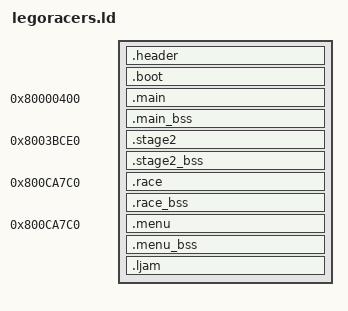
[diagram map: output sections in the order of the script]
SECTIONS
{
    __romPos = 0;
    header_ROM_START = __romPos;
    header_VRAM = ADDR(.header);
    .header : AT(header_ROM_START) SUBALIGN(16)
    {
        header_DATA_START = .;
        header_s = .;
        build/asm/header.s.o(.data);
        header_DATA_END = .;
    }
    __romPos += SIZEOF(.header);
    header_ROM_END = __romPos;
    header_VRAM_END = .;

    boot_ROM_START = __romPos;
    boot_VRAM = ADDR(.boot);
    .boot : AT(boot_ROM_START) SUBALIGN(16)
    {
        boot_DATA_START = .;
        boot_bin = .;
        build/assets/boot.bin.o(.data);
        boot_DATA_END = .;
    }
    __romPos += SIZEOF(.boot);
    boot_ROM_END = __romPos;
    boot_VRAM_END = .;

    main_ROM_START = __romPos;
    main_VRAM = ADDR(.main);
    .main 0x80000400 : AT(main_ROM_START) SUBALIGN(16)
    {
        main_TEXT_START = .;
        build/asm/1000.s.o(.text);
        main_DATA_START = .;
        main_RODATA_START = .;
        build/asm/data/libc.rdata.s.o(.rdata);
        build/asm/data/main_030.rdata.s.o(.rdata);
        build/asm/data/main/1150.rdata.s.o(.rdata);
        build/asm/data/main/1360.rdata.s.o(.rdata);
        build/asm/data/main/1800.rdata.s.o(.rdata);
        build/asm/data/main/1890.rdata.s.o(.rdata);
        build/asm/data/main/1A40.rdata.s.o(.rdata);
        build/asm/data/main/1C20.rdata.s.o(.rdata);
        build/asm/data/main/1C60.rdata.s.o(.rdata);
        build/asm/data/main/1CD0.rdata.s.o(.rdata);
        build/asm/data/main/1CF0.rdata.s.o(.rdata);
        build/asm/data/main/1D40.rdata.s.o(.rdata);
        build/asm/data/libsn/divdi3.rdata.s.o(.rdata);
        build/asm/data/libsn/udivdi3.rdata.s.o(.rdata);
        build/asm/data/libsn/umoddi3.rdata.s.o(.rdata);
        build/asm/data/libultra/setintmask.rodata.s.o(.rodata);
        build/asm/data/libultra/rodata.rodata.s.o(.rodata);
        build/asm/data/libultra/rodata2.rodata.s.o(.rodata);
        main_RODATA_END = .;
        build/asm/libc.s.o(.text);
        build/asm/main/010.s.o(.text);
        build/asm/main/020.s.o(.text);
        build/asm/main/030.s.o(.text);
        build/asm/main/040.s.o(.text);
        build/asm/main/050.s.o(.text);
        build/asm/main/060.s.o(.text);
        build/asm/main/070.s.o(.text);
        build/asm/main/080.s.o(.text);
        build/asm/main/090.s.o(.text);
        build/asm/main/100.s.o(.text);
        build/asm/main/110.s.o(.text);
        build/asm/main/120.s.o(.text);
        build/asm/main/130.s.o(.text);
        build/asm/main/140.s.o(.text);
        rspboot_bin = .;
        build/assets/rspboot.bin.o(.data);
        gspF3DEX2_NoN_fifoTextStart_bin = .;
        build/assets/gspF3DEX2_NoN_fifoTextStart.bin.o(.data);
        n_aspMain_text_text__bin = .;
        build/assets/n_aspMain.text.bin.o(.data);
        build/asm/libmus/player.s.o(.text);
        build/asm/libmus/player_fx.s.o(.text);
        build/asm/libmus/aud_dma.s.o(.text);
        build/asm/libmus/aud_sched.s.o(.text);
        build/asm/libmus/aud_thread.s.o(.text);
        build/asm/libmus/aud_samples.s.o(.text);
        build/asm/libmus/lib_memory.s.o(.text);
        build/asm/libaudio/n_auxbux.s.o(.text);
        build/asm/libaudio/n_drverNew.s.o(.text);
        build/asm/libaudio/n_env.s.o(.text);
        build/asm/libaudio/0x147A0.s.o(.text);
        build/asm/libaudio/n_resample.s.o(.text);
        build/asm/libaudio/x147A0.s.o(.text);
        build/asm/libaudio/n_synaddplayer.s.o(.text);
        build/asm/libaudio/n_synallocvoice.s.o(.text);
        build/asm/libaudio/0x15DA0.s.o(.text);
        build/asm/libaudio/0x15F50.s.o(.text);
        build/asm/libaudio/0x15FE0.s.o(.text);
        build/asm/libaudio/n_synthesiser.s.o(.text);
        build/asm/libaudio/n_save.s.o(.text);
        build/asm/libaudio/n_mainbus.s.o(.text);
        build/asm/libaudio/n_syncallocfx.s.o(.text);
        build/asm/libultra/osSetIntMask.s.o(.text);
        build/asm/libultra/osPiRawStartDma.s.o(.text);
        build/asm/libultra/16C20.s.o(.text);
        build/asm/libultra/16CC0.s.o(.text);
        build/asm/libultra/16E60.s.o(.text);
        build/asm/libultra/17220.s.o(.text);
        build/asm/libultra/172B0.s.o(.text);
        build/asm/libultra/17420.s.o(.text);
        build/asm/libultra/17590.s.o(.text);
        build/asm/libultra/17680.s.o(.text);
        build/asm/libultra/17730.s.o(.text);
        build/asm/libultra/17870.s.o(.text);
        build/asm/libultra/17910.s.o(.text);
        build/asm/libultra/17930.s.o(.text);
        build/asm/libultra/18160.s.o(.text);
        build/asm/libultra/18C70.s.o(.text);
        build/asm/libultra/18D80.s.o(.text);
        build/asm/libultra/19A50.s.o(.text);
        build/asm/libultra/19E70.s.o(.text);
        build/asm/libultra/1AA10.s.o(.text);
        build/asm/libultra/1AB90.s.o(.text);
        build/asm/libultra/1ABD0.s.o(.text);
        build/asm/libultra/1AC20.s.o(.text);
        build/asm/libultra/1AC60.s.o(.text);
        build/asm/libultra/1B2A0.s.o(.text);
        build/asm/libultra/1B2B0.s.o(.text);
        build/asm/libultra/1B350.s.o(.text);
        build/asm/libultra/1B480.s.o(.text);
        build/asm/libultra/1B500.s.o(.text);
        build/asm/libultra/1B530.s.o(.text);
        build/asm/libultra/1B7B0.s.o(.text);
        build/asm/libultra/1BAC0.s.o(.text);
        build/asm/libultra/1BB20.s.o(.text);
        build/asm/libultra/1BB30.s.o(.text);
        build/asm/libultra/1BF00.s.o(.text);
        build/asm/libultra/1C450.s.o(.text);
        build/asm/libultra/1C4E0.s.o(.text);
        build/asm/libultra/1CF10.s.o(.text);
        build/asm/libultra/1D160.s.o(.text);
        build/asm/libultra/1D320.s.o(.text);
        build/asm/libultra/1DDA0.s.o(.text);
        build/asm/libultra/1DDD0.s.o(.text);
        build/asm/libultra/1DF10.s.o(.text);
        build/asm/libultra/1E880.s.o(.text);
        build/asm/libultra/1E9B0.s.o(.text);
        build/asm/libultra/1EB90.s.o(.text);
        build/asm/libultra/1EDD0.s.o(.text);
        build/asm/libultra/1F110.s.o(.text);
        build/asm/libultra/1F1E0.s.o(.text);
        build/asm/libultra/1F200.s.o(.text);
        build/asm/libultra/1F250.s.o(.text);
        build/asm/libultra/1FD10.s.o(.text);
        build/asm/libultra/1FD30.s.o(.text);
        build/asm/libultra/1FDE0.s.o(.text);
        build/asm/libultra/1FED0.s.o(.text);
        build/asm/libultra/20080.s.o(.text);
        build/asm/libultra/200A0.s.o(.text);
        build/asm/libultra/20170.s.o(.text);
        build/asm/libultra/20290.s.o(.text);
        build/asm/libultra/20350.s.o(.text);
        build/asm/libultra/20390.s.o(.text);
        build/asm/libultra/203E0.s.o(.text);
        build/asm/libultra/20470.s.o(.text);
        build/asm/libultra/20480.s.o(.text);
        build/asm/libultra/20520.s.o(.text);
        build/asm/libultra/20820.s.o(.text);
        build/asm/libultra/20830.s.o(.text);
        build/asm/libultra/208F0.s.o(.text);
        build/asm/libultra/20940.s.o(.text);
        build/asm/libultra/20980.s.o(.text);
        build/asm/libultra/20A90.s.o(.text);
        build/asm/libultra/20AD0.s.o(.text);
        build/asm/libultra/20E10.s.o(.text);
        build/asm/libultra/20E20.s.o(.text);
        build/asm/libultra/20E80.s.o(.text);
        build/asm/libultra/20ED0.s.o(.text);
        build/asm/libultra/21040.s.o(.text);
        build/asm/libultra/21090.s.o(.text);
        build/asm/libultra/213A0.s.o(.text);
        build/asm/libultra/21400.s.o(.text);
        build/asm/libultra/21790.s.o(.text);
        build/asm/libultra/21880.s.o(.text);
        build/asm/libultra/21CB0.s.o(.text);
        build/asm/libultra/21ED0.s.o(.text);
        build/asm/libultra/224B0.s.o(.text);
        build/asm/libultra/22670.s.o(.text);
        build/asm/libultra/22950.s.o(.text);
        build/asm/libultra/22A60.s.o(.text);
        build/asm/libultra/22E30.s.o(.text);
        build/asm/libultra/236C0.s.o(.text);
        build/asm/libultra/238D0.s.o(.text);
        build/asm/libultra/23940.s.o(.text);
        build/asm/libultra/243D0.s.o(.text);
        build/asm/libultra/245C0.s.o(.text);
        build/asm/libultra/24830.s.o(.text);
        build/asm/libultra/24B20.s.o(.text);
        build/asm/libultra/24B30.s.o(.text);
        build/asm/libultra/24BA0.s.o(.text);
        build/asm/libultra/24BC0.s.o(.text);
        build/asm/libultra/24C10.s.o(.text);
        build/asm/libsn/divdi3.s.o(.text);
        build/asm/libsn/udivdi3.s.o(.text);
        build/asm/libsn/umoddi3.s.o(.text);
        build/asm/alloc.s.o(.text);
        build/asm/__builtin_delete.s.o(.text);
        main_TEXT_END = .;
        main_25D30_data__s = .;
        build/asm/data/main/25D30.data.s.o(.data);
        main_25E40_data__s = .;
        build/asm/data/main/25E40.data.s.o(.data);
        main_27EA0_data__s = .;
        build/asm/data/main/27EA0.data.s.o(.data);
        main_306C0_data__s = .;
        build/asm/data/main/306C0.data.s.o(.data);
        main_30950_data__s = .;
        build/asm/data/main/30950.data.s.o(.data);
        main_30960_data__s = .;
        build/asm/data/main/30960.data.s.o(.data);
        main_30970_data__s = .;
        build/asm/data/main/30970.data.s.o(.data);
        main_309D0_data__s = .;
        build/asm/data/main/309D0.data.s.o(.data);
        main_309E0_data__s = .;
        build/asm/data/main/309E0.data.s.o(.data);
        main_309F0_data__s = .;
        build/asm/data/main/309F0.data.s.o(.data);
        main_30C00_data__s = .;
        build/asm/data/main/30C00.data.s.o(.data);
        gspF3DEX2_NoN_fifoDataStart_bin = .;
        build/assets/gspF3DEX2_NoN_fifoDataStart.bin.o(.data);
        n_aspMain_data_bin = .;
        build/assets/n_aspMain_data.bin.o(.data);
        lib_313A0_data__s = .;
        build/asm/data/lib/313A0.data.s.o(.data);
        lib_315D0_data__s = .;
        build/asm/data/lib/315D0.data.s.o(.data);
        lib_315E0_data__s = .;
        build/asm/data/lib/315E0.data.s.o(.data);
        lib_31880_data__s = .;
        build/asm/data/lib/31880.data.s.o(.data);
        lib_31890_data__s = .;
        build/asm/data/lib/31890.data.s.o(.data);
        main_DATA_END = .;
    }
    main_bss_VRAM = ADDR(.main_bss);
    .main_bss (NOLOAD) : SUBALIGN(16)
    {
        main_BSS_START = .;
        build/asm/1000.s.o(.bss);
        build/asm/libc.s.o(.bss);
        build/asm/main/010.s.o(.bss);
        build/asm/main/020.s.o(.bss);
        build/asm/main/030.s.o(.bss);
        build/asm/main/040.s.o(.bss);
        build/asm/main/050.s.o(.bss);
        build/asm/main/060.s.o(.bss);
        build/asm/main/070.s.o(.bss);
        build/asm/main/080.s.o(.bss);
        build/asm/main/090.s.o(.bss);
        build/asm/main/100.s.o(.bss);
        build/asm/main/110.s.o(.bss);
        build/asm/main/120.s.o(.bss);
        build/asm/main/130.s.o(.bss);
        build/asm/main/140.s.o(.bss);
        build/asm/libmus/player.s.o(.bss);
        build/asm/libmus/player_fx.s.o(.bss);
        build/asm/libmus/aud_dma.s.o(.bss);
        build/asm/libmus/aud_sched.s.o(.bss);
        build/asm/libmus/aud_thread.s.o(.bss);
        build/asm/libmus/aud_samples.s.o(.bss);
        build/asm/libmus/lib_memory.s.o(.bss);
        build/asm/libaudio/n_auxbux.s.o(.bss);
        build/asm/libaudio/n_drverNew.s.o(.bss);
        build/asm/libaudio/n_env.s.o(.bss);
        build/asm/libaudio/0x147A0.s.o(.bss);
        build/asm/libaudio/n_resample.s.o(.bss);
        build/asm/libaudio/x147A0.s.o(.bss);
        build/asm/libaudio/n_synaddplayer.s.o(.bss);
        build/asm/libaudio/n_synallocvoice.s.o(.bss);
        build/asm/libaudio/0x15DA0.s.o(.bss);
        build/asm/libaudio/0x15F50.s.o(.bss);
        build/asm/libaudio/0x15FE0.s.o(.bss);
        build/asm/libaudio/n_synthesiser.s.o(.bss);
        build/asm/libaudio/n_save.s.o(.bss);
        build/asm/libaudio/n_mainbus.s.o(.bss);
        build/asm/libaudio/n_syncallocfx.s.o(.bss);
        build/asm/libultra/osSetIntMask.s.o(.bss);
        build/asm/libultra/osPiRawStartDma.s.o(.bss);
        build/asm/libultra/16C20.s.o(.bss);
        build/asm/libultra/16CC0.s.o(.bss);
        build/asm/libultra/16E60.s.o(.bss);
        build/asm/libultra/17220.s.o(.bss);
        build/asm/libultra/172B0.s.o(.bss);
        build/asm/libultra/17420.s.o(.bss);
        build/asm/libultra/17590.s.o(.bss);
        build/asm/libultra/17680.s.o(.bss);
        build/asm/libultra/17730.s.o(.bss);
        build/asm/libultra/17870.s.o(.bss);
        build/asm/libultra/17910.s.o(.bss);
        build/asm/libultra/17930.s.o(.bss);
        build/asm/libultra/18160.s.o(.bss);
        build/asm/libultra/18C70.s.o(.bss);
        build/asm/libultra/18D80.s.o(.bss);
        build/asm/libultra/19A50.s.o(.bss);
        build/asm/libultra/19E70.s.o(.bss);
        build/asm/libultra/1AA10.s.o(.bss);
        build/asm/libultra/1AB90.s.o(.bss);
        build/asm/libultra/1ABD0.s.o(.bss);
        build/asm/libultra/1AC20.s.o(.bss);
        build/asm/libultra/1AC60.s.o(.bss);
        build/asm/libultra/1B2A0.s.o(.bss);
        build/asm/libultra/1B2B0.s.o(.bss);
        build/asm/libultra/1B350.s.o(.bss);
        build/asm/libultra/1B480.s.o(.bss);
        build/asm/libultra/1B500.s.o(.bss);
        build/asm/libultra/1B530.s.o(.bss);
        build/asm/libultra/1B7B0.s.o(.bss);
        build/asm/libultra/1BAC0.s.o(.bss);
        build/asm/libultra/1BB20.s.o(.bss);
        build/asm/libultra/1BB30.s.o(.bss);
        build/asm/libultra/1BF00.s.o(.bss);
        build/asm/libultra/1C450.s.o(.bss);
        build/asm/libultra/1C4E0.s.o(.bss);
        build/asm/libultra/1CF10.s.o(.bss);
        build/asm/libultra/1D160.s.o(.bss);
        build/asm/libultra/1D320.s.o(.bss);
        build/asm/libultra/1DDA0.s.o(.bss);
        build/asm/libultra/1DDD0.s.o(.bss);
        build/asm/libultra/1DF10.s.o(.bss);
        build/asm/libultra/1E880.s.o(.bss);
        build/asm/libultra/1E9B0.s.o(.bss);
        build/asm/libultra/1EB90.s.o(.bss);
        build/asm/libultra/1EDD0.s.o(.bss);
        build/asm/libultra/1F110.s.o(.bss);
        build/asm/libultra/1F1E0.s.o(.bss);
        build/asm/libultra/1F200.s.o(.bss);
        build/asm/libultra/1F250.s.o(.bss);
        build/asm/libultra/1FD10.s.o(.bss);
        build/asm/libultra/1FD30.s.o(.bss);
        build/asm/libultra/1FDE0.s.o(.bss);
        build/asm/libultra/1FED0.s.o(.bss);
        build/asm/libultra/20080.s.o(.bss);
        build/asm/libultra/200A0.s.o(.bss);
        build/asm/libultra/20170.s.o(.bss);
        build/asm/libultra/20290.s.o(.bss);
        build/asm/libultra/20350.s.o(.bss);
        build/asm/libultra/20390.s.o(.bss);
        build/asm/libultra/203E0.s.o(.bss);
        build/asm/libultra/20470.s.o(.bss);
        build/asm/libultra/20480.s.o(.bss);
        build/asm/libultra/20520.s.o(.bss);
        build/asm/libultra/20820.s.o(.bss);
        build/asm/libultra/20830.s.o(.bss);
        build/asm/libultra/208F0.s.o(.bss);
        build/asm/libultra/20940.s.o(.bss);
        build/asm/libultra/20980.s.o(.bss);
        build/asm/libultra/20A90.s.o(.bss);
        build/asm/libultra/20AD0.s.o(.bss);
        build/asm/libultra/20E10.s.o(.bss);
        build/asm/libultra/20E20.s.o(.bss);
        build/asm/libultra/20E80.s.o(.bss);
        build/asm/libultra/20ED0.s.o(.bss);
        build/asm/libultra/21040.s.o(.bss);
        build/asm/libultra/21090.s.o(.bss);
        build/asm/libultra/213A0.s.o(.bss);
        build/asm/libultra/21400.s.o(.bss);
        build/asm/libultra/21790.s.o(.bss);
        build/asm/libultra/21880.s.o(.bss);
        build/asm/libultra/21CB0.s.o(.bss);
        build/asm/libultra/21ED0.s.o(.bss);
        build/asm/libultra/224B0.s.o(.bss);
        build/asm/libultra/22670.s.o(.bss);
        build/asm/libultra/22950.s.o(.bss);
        build/asm/libultra/22A60.s.o(.bss);
        build/asm/libultra/22E30.s.o(.bss);
        build/asm/libultra/236C0.s.o(.bss);
        build/asm/libultra/238D0.s.o(.bss);
        build/asm/libultra/23940.s.o(.bss);
        build/asm/libultra/243D0.s.o(.bss);
        build/asm/libultra/245C0.s.o(.bss);
        build/asm/libultra/24830.s.o(.bss);
        build/asm/libultra/24B20.s.o(.bss);
        build/asm/libultra/24B30.s.o(.bss);
        build/asm/libultra/24BA0.s.o(.bss);
        build/asm/libultra/24BC0.s.o(.bss);
        build/asm/libultra/24C10.s.o(.bss);
        build/asm/libsn/divdi3.s.o(.bss);
        build/asm/libsn/udivdi3.s.o(.bss);
        build/asm/libsn/umoddi3.s.o(.bss);
        build/asm/alloc.s.o(.bss);
        build/asm/__builtin_delete.s.o(.bss);
        main_BSS_END = .;
    }
    __romPos += SIZEOF(.main);
    __romPos = (__romPos + 15) & ~15; /* align 16 */
    main_ROM_END = __romPos;
    main_VRAM_END = .;

    stage2_ROM_START = __romPos;
    stage2_VRAM = ADDR(.stage2);
    .stage2 0x8003BCE0 : AT(stage2_ROM_START) SUBALIGN(16)
    {
        stage2_RODATA_START = .;
        build/asm/data/stage2/010a.rdata.s.o(.rdata);
        stage2_DATA_START = .;
        build/asm/data/stage2/010b.rdata.s.o(.rdata);
        build/asm/data/stage2/010c.rdata.s.o(.rdata);
        build/asm/data/stage2/030.rdata.s.o(.rdata);
        build/asm/data/stage2/040.rdata.s.o(.rdata);
        build/asm/data/stage2/050a.rdata.s.o(.rdata);
        build/asm/data/stage2/050b.rdata.s.o(.rdata);
        build/asm/data/stage2/060.rdata.s.o(.rdata);
        build/asm/data/stage2/070.rdata.s.o(.rdata);
        build/asm/data/stage2/080.rdata.s.o(.rdata);
        build/asm/data/stage2/090.rdata.s.o(.rdata);
        build/asm/data/stage2/100.rdata.s.o(.rdata);
        build/asm/data/stage2/110.rdata.s.o(.rdata);
        build/asm/data/stage2/120.rdata.s.o(.rdata);
        build/asm/data/stage2/130.rdata.s.o(.rdata);
        build/asm/data/stage2/140.rdata.s.o(.rdata);
        build/asm/data/stage2/150.rdata.s.o(.rdata);
        build/asm/data/stage2/160.rdata.s.o(.rdata);
        build/asm/data/stage2/170.rdata.s.o(.rdata);
        build/asm/data/stage2/180.rdata.s.o(.rdata);
        build/asm/data/stage2/190.rdata.s.o(.rdata);
        build/asm/data/stage2/200a.rdata.s.o(.rdata);
        build/asm/data/stage2/200b.rdata.s.o(.rdata);
        build/asm/data/stage2/210.rdata.s.o(.rdata);
        build/asm/data/stage2/220.rdata.s.o(.rdata);
        build/asm/data/stage2/230.rdata.s.o(.rdata);
        build/asm/data/stage2/240.rdata.s.o(.rdata);
        build/asm/data/stage2/250.rdata.s.o(.rdata);
        build/asm/data/stage2/260.rdata.s.o(.rdata);
        build/asm/data/stage2/270.rdata.s.o(.rdata);
        build/asm/data/stage2/280.rdata.s.o(.rdata);
        build/asm/data/stage2/290.rdata.s.o(.rdata);
        build/asm/data/stage2/300a.rdata.s.o(.rdata);
        build/asm/data/stage2/300b.rdata.s.o(.rdata);
        build/asm/data/stage2/310.rdata.s.o(.rdata);
        build/asm/data/stage2/320.rdata.s.o(.rdata);
        build/asm/data/stage2/330.rdata.s.o(.rdata);
        build/asm/data/stage2/340.rdata.s.o(.rdata);
        build/asm/data/stage2/350.rdata.s.o(.rdata);
        build/asm/data/stage2/360.rdata.s.o(.rdata);
        build/asm/data/stage2/370.rdata.s.o(.rdata);
        build/asm/data/stage2/380.rdata.s.o(.rdata);
        build/asm/data/stage2/390.rdata.s.o(.rdata);
        build/asm/data/stage2/400.rdata.s.o(.rdata);
        build/asm/data/stage2/410.rdata.s.o(.rdata);
        build/asm/data/stage2/420.rdata.s.o(.rdata);
        build/asm/data/stage2/430.rdata.s.o(.rdata);
        build/asm/data/stage2/440.rdata.s.o(.rdata);
        build/asm/data/stage2/450.rdata.s.o(.rdata);
        build/asm/data/stage2/460.rdata.s.o(.rdata);
        build/asm/data/stage2/470.rdata.s.o(.rdata);
        build/asm/data/stage2/480.rdata.s.o(.rdata);
        build/asm/data/stage2/490.rdata.s.o(.rdata);
        build/asm/data/stage2/500.rdata.s.o(.rdata);
        build/asm/data/stage2/510.rdata.s.o(.rdata);
        build/asm/data/stage2/520.rdata.s.o(.rdata);
        build/asm/data/stage2/530.rdata.s.o(.rdata);
        build/asm/data/stage2/550.rdata.s.o(.rdata);
        build/asm/data/stage2/560.rdata.s.o(.rdata);
        build/asm/data/stage2/570.rdata.s.o(.rdata);
        build/asm/data/stage2/580.rdata.s.o(.rdata);
        build/asm/data/stage2/590.rdata.s.o(.rdata);
        build/asm/data/stage2/600.rdata.s.o(.rdata);
        build/asm/data/stage2/610.rdata.s.o(.rdata);
        build/asm/data/stage2/620a.rdata.s.o(.rdata);
        build/asm/data/stage2/620b.rdata.s.o(.rdata);
        build/asm/data/stage2/630.rdata.s.o(.rdata);
        build/asm/data/stage2/640.rdata.s.o(.rdata);
        build/asm/data/stage2/650.rdata.s.o(.rdata);
        build/asm/data/stage2/660.rdata.s.o(.rdata);
        build/asm/data/stage2/670a.rdata.s.o(.rdata);
        build/asm/data/stage2/670b.rdata.s.o(.rdata);
        build/asm/data/stage2/680.rdata.s.o(.rdata);
        build/asm/data/stage2/690.rdata.s.o(.rdata);
        build/asm/data/stage2/700.rdata.s.o(.rdata);
        build/asm/data/stage2/720.rdata.s.o(.rdata);
        build/asm/data/stage2/740.rdata.s.o(.rdata);
        build/asm/data/stage2/750.rdata.s.o(.rdata);
        build/asm/data/stage2/760a.rdata.s.o(.rdata);
        build/asm/data/stage2/760b.rdata.s.o(.rdata);
        build/asm/data/stage2/760c.rdata.s.o(.rdata);
        build/asm/data/stage2/770.rdata.s.o(.rdata);
        build/asm/data/stage2/780.rdata.s.o(.rdata);
        build/asm/data/stage2/790.rdata.s.o(.rdata);
        build/asm/data/stage2/800.rdata.s.o(.rdata);
        build/asm/data/stage2/810.rdata.s.o(.rdata);
        stage2_080_ctor_ctor__data__s = .;
        build/asm/data/stage2/080.ctor.data.s.o(.data);
        stage2_180a_ctor_ctor__data__s = .;
        build/asm/data/stage2/180a.ctor.data.s.o(.data);
        stage2_180b_ctor_ctor__data__s = .;
        build/asm/data/stage2/180b.ctor.data.s.o(.data);
        stage2_670_ctor_ctor__data__s = .;
        build/asm/data/stage2/670.ctor.data.s.o(.data);
        stage2_730_ctor_ctor__data__s = .;
        build/asm/data/stage2/730.ctor.data.s.o(.data);
        stage2_080_dtor_dtor__data__s = .;
        build/asm/data/stage2/080.dtor.data.s.o(.data);
        stage2_180a_dtor_dtor__data__s = .;
        build/asm/data/stage2/180a.dtor.data.s.o(.data);
        stage2_180b_dtor_dtor__data__s = .;
        build/asm/data/stage2/180b.dtor.data.s.o(.data);
        stage2_670_dtor_dtor__data__s = .;
        build/asm/data/stage2/670.dtor.data.s.o(.data);
        stage2_TEXT_START = .;
        build/asm/stage2/010.s.o(.text);
        build/asm/stage2/020.s.o(.text);
        build/asm/stage2/030.s.o(.text);
        build/asm/stage2/040.s.o(.text);
        build/asm/stage2/050.s.o(.text);
        build/asm/stage2/060.s.o(.text);
        build/asm/stage2/070.s.o(.text);
        build/asm/stage2/080.s.o(.text);
        build/asm/stage2/090.s.o(.text);
        build/asm/stage2/100.s.o(.text);
        build/asm/stage2/110.s.o(.text);
        build/asm/stage2/120.s.o(.text);
        build/asm/stage2/130.s.o(.text);
        build/asm/stage2/140.s.o(.text);
        build/asm/stage2/150.s.o(.text);
        build/asm/stage2/160.s.o(.text);
        build/asm/stage2/170.s.o(.text);
        build/asm/stage2/180.s.o(.text);
        build/asm/stage2/190.s.o(.text);
        build/asm/stage2/200.s.o(.text);
        build/asm/stage2/210.s.o(.text);
        build/asm/stage2/220.s.o(.text);
        build/asm/stage2/230.s.o(.text);
        build/asm/stage2/240.s.o(.text);
        build/asm/stage2/250.s.o(.text);
        build/asm/stage2/260.s.o(.text);
        build/asm/stage2/270.s.o(.text);
        build/asm/stage2/280.s.o(.text);
        build/asm/stage2/290.s.o(.text);
        build/asm/stage2/300.s.o(.text);
        build/asm/stage2/310.s.o(.text);
        build/asm/stage2/320.s.o(.text);
        build/asm/stage2/330.s.o(.text);
        build/asm/stage2/340.s.o(.text);
        build/asm/stage2/350.s.o(.text);
        build/asm/stage2/360.s.o(.text);
        build/asm/stage2/370.s.o(.text);
        build/asm/stage2/380.s.o(.text);
        build/asm/stage2/390.s.o(.text);
        build/asm/stage2/400.s.o(.text);
        build/asm/stage2/410.s.o(.text);
        build/asm/stage2/420.s.o(.text);
        build/asm/stage2/430.s.o(.text);
        build/asm/stage2/440.s.o(.text);
        build/asm/stage2/450.s.o(.text);
        build/asm/stage2/460.s.o(.text);
        build/asm/stage2/470.s.o(.text);
        build/asm/stage2/480.s.o(.text);
        build/asm/stage2/490.s.o(.text);
        build/asm/stage2/500.s.o(.text);
        build/asm/stage2/510.s.o(.text);
        build/asm/stage2/520.s.o(.text);
        build/asm/stage2/530.s.o(.text);
        build/asm/stage2/540.s.o(.text);
        build/asm/stage2/550.s.o(.text);
        build/asm/stage2/560.s.o(.text);
        build/asm/stage2/570.s.o(.text);
        build/asm/stage2/580.s.o(.text);
        build/asm/stage2/590.s.o(.text);
        build/asm/stage2/600.s.o(.text);
        build/asm/stage2/610.s.o(.text);
        build/asm/stage2/620.s.o(.text);
        build/asm/stage2/630.s.o(.text);
        build/asm/stage2/640.s.o(.text);
        build/asm/stage2/650.s.o(.text);
        build/asm/stage2/660.s.o(.text);
        build/asm/stage2/670.s.o(.text);
        build/asm/stage2/680.s.o(.text);
        build/asm/stage2/690.s.o(.text);
        build/asm/stage2/700.s.o(.text);
        build/asm/stage2/710.s.o(.text);
        build/asm/stage2/720.s.o(.text);
        build/asm/stage2/730.s.o(.text);
        build/asm/stage2/740.s.o(.text);
        build/asm/stage2/750.s.o(.text);
        build/asm/stage2/760.s.o(.text);
        build/asm/stage2/770.s.o(.text);
        build/asm/stage2/780.s.o(.text);
        build/asm/stage2/790.s.o(.text);
        build/asm/stage2/800.s.o(.text);
        build/asm/stage2/810.s.o(.text);
        stage2_TEXT_END = .;
        stage2_010_data__s = .;
        build/asm/data/stage2/010.data.s.o(.data);
        stage2_030a_data__s = .;
        build/asm/data/stage2/030a.data.s.o(.data);
        stage2_030b_data__s = .;
        build/asm/data/stage2/030b.data.s.o(.data);
        stage2_040_data__s = .;
        build/asm/data/stage2/040.data.s.o(.data);
        stage2_050a_data__s = .;
        build/asm/data/stage2/050a.data.s.o(.data);
        stage2_050b_data__s = .;
        build/asm/data/stage2/050b.data.s.o(.data);
        stage2_070_data__s = .;
        build/asm/data/stage2/070.data.s.o(.data);
        stage2_070_080_data__s = .;
        build/asm/data/stage2/070-080.data.s.o(.data);
        stage2_100_data__s = .;
        build/asm/data/stage2/100.data.s.o(.data);
        stage2_180a_data__s = .;
        build/asm/data/stage2/180a.data.s.o(.data);
        stage2_180b_data__s = .;
        build/asm/data/stage2/180b.data.s.o(.data);
        stage2_190_data__s = .;
        build/asm/data/stage2/190.data.s.o(.data);
        stage2_210_data__s = .;
        build/asm/data/stage2/210.data.s.o(.data);
        stage2_230_data__s = .;
        build/asm/data/stage2/230.data.s.o(.data);
        stage2_250_data__s = .;
        build/asm/data/stage2/250.data.s.o(.data);
        stage2_260a_data__s = .;
        build/asm/data/stage2/260a.data.s.o(.data);
        stage2_260b_data__s = .;
        build/asm/data/stage2/260b.data.s.o(.data);
        stage2_280_data__s = .;
        build/asm/data/stage2/280.data.s.o(.data);
        stage2_290_data__s = .;
        build/asm/data/stage2/290.data.s.o(.data);
        stage2_300a_data__s = .;
        build/asm/data/stage2/300a.data.s.o(.data);
        stage2_300b_data__s = .;
        build/asm/data/stage2/300b.data.s.o(.data);
        stage2_310_data__s = .;
        build/asm/data/stage2/310.data.s.o(.data);
        stage2_320_data__s = .;
        build/asm/data/stage2/320.data.s.o(.data);
        stage2_330_data__s = .;
        build/asm/data/stage2/330.data.s.o(.data);
        stage2_360_data__s = .;
        build/asm/data/stage2/360.data.s.o(.data);
        stage2_380_data__s = .;
        build/asm/data/stage2/380.data.s.o(.data);
        stage2_390_data__s = .;
        build/asm/data/stage2/390.data.s.o(.data);
        stage2_450_460_data__s = .;
        build/asm/data/stage2/450-460.data.s.o(.data);
        stage2_470_data__s = .;
        build/asm/data/stage2/470.data.s.o(.data);
        stage2_480_data__s = .;
        build/asm/data/stage2/480.data.s.o(.data);
        stage2_490_data__s = .;
        build/asm/data/stage2/490.data.s.o(.data);
        stage2_510_data__s = .;
        build/asm/data/stage2/510.data.s.o(.data);
        stage2_520_data__s = .;
        build/asm/data/stage2/520.data.s.o(.data);
        stage2_550_data__s = .;
        build/asm/data/stage2/550.data.s.o(.data);
        stage2_570_data__s = .;
        build/asm/data/stage2/570.data.s.o(.data);
        stage2_580_590_data__s = .;
        build/asm/data/stage2/580-590.data.s.o(.data);
        stage2_590_600_data__s = .;
        build/asm/data/stage2/590-600.data.s.o(.data);
        stage2_610_data__s = .;
        build/asm/data/stage2/610.data.s.o(.data);
        stage2_620_data__s = .;
        build/asm/data/stage2/620.data.s.o(.data);
        stage2_630_640_data__s = .;
        build/asm/data/stage2/630-640.data.s.o(.data);
        stage2_660_data__s = .;
        build/asm/data/stage2/660.data.s.o(.data);
        stage2_680_data__s = .;
        build/asm/data/stage2/680.data.s.o(.data);
        stage2_700_data__s = .;
        build/asm/data/stage2/700.data.s.o(.data);
        stage2_730_data__s = .;
        build/asm/data/stage2/730.data.s.o(.data);
        stage2_760_data__s = .;
        build/asm/data/stage2/760.data.s.o(.data);
        stage2_770_data__s = .;
        build/asm/data/stage2/770.data.s.o(.data);
        stage2_780_data__s = .;
        build/asm/data/stage2/780.data.s.o(.data);
        stage2_790_data__s = .;
        build/asm/data/stage2/790.data.s.o(.data);
        stage2_800_data__s = .;
        build/asm/data/stage2/800.data.s.o(.data);
        stage2_DATA_END = .;
        build/asm/stage2/010.s.o(.rodata);
        build/asm/stage2/020.s.o(.rodata);
        build/asm/stage2/030.s.o(.rodata);
        build/asm/stage2/040.s.o(.rodata);
        build/asm/stage2/050.s.o(.rodata);
        build/asm/stage2/060.s.o(.rodata);
        build/asm/stage2/070.s.o(.rodata);
        build/asm/stage2/080.s.o(.rodata);
        build/asm/stage2/090.s.o(.rodata);
        build/asm/stage2/100.s.o(.rodata);
        build/asm/stage2/110.s.o(.rodata);
        build/asm/stage2/120.s.o(.rodata);
        build/asm/stage2/130.s.o(.rodata);
        build/asm/stage2/140.s.o(.rodata);
        build/asm/stage2/150.s.o(.rodata);
        build/asm/stage2/160.s.o(.rodata);
        build/asm/stage2/170.s.o(.rodata);
        build/asm/stage2/180.s.o(.rodata);
        build/asm/stage2/190.s.o(.rodata);
        build/asm/stage2/200.s.o(.rodata);
        build/asm/stage2/210.s.o(.rodata);
        build/asm/stage2/220.s.o(.rodata);
        build/asm/stage2/230.s.o(.rodata);
        build/asm/stage2/240.s.o(.rodata);
        build/asm/stage2/250.s.o(.rodata);
        build/asm/stage2/260.s.o(.rodata);
        build/asm/stage2/270.s.o(.rodata);
        build/asm/stage2/280.s.o(.rodata);
        build/asm/stage2/290.s.o(.rodata);
        build/asm/stage2/300.s.o(.rodata);
        build/asm/stage2/310.s.o(.rodata);
        build/asm/stage2/320.s.o(.rodata);
        build/asm/stage2/330.s.o(.rodata);
        build/asm/stage2/340.s.o(.rodata);
        build/asm/stage2/350.s.o(.rodata);
        build/asm/stage2/360.s.o(.rodata);
        build/asm/stage2/370.s.o(.rodata);
        build/asm/stage2/380.s.o(.rodata);
        build/asm/stage2/390.s.o(.rodata);
        build/asm/stage2/400.s.o(.rodata);
        build/asm/stage2/410.s.o(.rodata);
        build/asm/stage2/420.s.o(.rodata);
        build/asm/stage2/430.s.o(.rodata);
        build/asm/stage2/440.s.o(.rodata);
        build/asm/stage2/450.s.o(.rodata);
        build/asm/stage2/460.s.o(.rodata);
        build/asm/stage2/470.s.o(.rodata);
        build/asm/stage2/480.s.o(.rodata);
        build/asm/stage2/490.s.o(.rodata);
        build/asm/stage2/500.s.o(.rodata);
        build/asm/stage2/510.s.o(.rodata);
        build/asm/stage2/520.s.o(.rodata);
        build/asm/stage2/530.s.o(.rodata);
        build/asm/stage2/540.s.o(.rodata);
        build/asm/stage2/550.s.o(.rodata);
        build/asm/stage2/560.s.o(.rodata);
        build/asm/stage2/570.s.o(.rodata);
        build/asm/stage2/580.s.o(.rodata);
        build/asm/stage2/590.s.o(.rodata);
        build/asm/stage2/600.s.o(.rodata);
        build/asm/stage2/610.s.o(.rodata);
        build/asm/stage2/620.s.o(.rodata);
        build/asm/stage2/630.s.o(.rodata);
        build/asm/stage2/640.s.o(.rodata);
        build/asm/stage2/650.s.o(.rodata);
        build/asm/stage2/660.s.o(.rodata);
        build/asm/stage2/670.s.o(.rodata);
        build/asm/stage2/680.s.o(.rodata);
        build/asm/stage2/690.s.o(.rodata);
        build/asm/stage2/700.s.o(.rodata);
        build/asm/stage2/710.s.o(.rodata);
        build/asm/stage2/720.s.o(.rodata);
        build/asm/stage2/730.s.o(.rodata);
        build/asm/stage2/740.s.o(.rodata);
        build/asm/stage2/750.s.o(.rodata);
        build/asm/stage2/760.s.o(.rodata);
        build/asm/stage2/770.s.o(.rodata);
        build/asm/stage2/780.s.o(.rodata);
        build/asm/stage2/790.s.o(.rodata);
        build/asm/stage2/800.s.o(.rodata);
        build/asm/stage2/810.s.o(.rodata);
        stage2_RODATA_END = .;
    }
    stage2_bss_VRAM = ADDR(.stage2_bss);
    .stage2_bss (NOLOAD) : SUBALIGN(16)
    {
        stage2_BSS_START = .;
        build/asm/stage2/010.s.o(.bss);
        build/asm/stage2/020.s.o(.bss);
        build/asm/stage2/030.s.o(.bss);
        build/asm/stage2/040.s.o(.bss);
        build/asm/stage2/050.s.o(.bss);
        build/asm/stage2/060.s.o(.bss);
        build/asm/stage2/070.s.o(.bss);
        build/asm/stage2/080.s.o(.bss);
        build/asm/stage2/090.s.o(.bss);
        build/asm/stage2/100.s.o(.bss);
        build/asm/stage2/110.s.o(.bss);
        build/asm/stage2/120.s.o(.bss);
        build/asm/stage2/130.s.o(.bss);
        build/asm/stage2/140.s.o(.bss);
        build/asm/stage2/150.s.o(.bss);
        build/asm/stage2/160.s.o(.bss);
        build/asm/stage2/170.s.o(.bss);
        build/asm/stage2/180.s.o(.bss);
        build/asm/stage2/190.s.o(.bss);
        build/asm/stage2/200.s.o(.bss);
        build/asm/stage2/210.s.o(.bss);
        build/asm/stage2/220.s.o(.bss);
        build/asm/stage2/230.s.o(.bss);
        build/asm/stage2/240.s.o(.bss);
        build/asm/stage2/250.s.o(.bss);
        build/asm/stage2/260.s.o(.bss);
        build/asm/stage2/270.s.o(.bss);
        build/asm/stage2/280.s.o(.bss);
        build/asm/stage2/290.s.o(.bss);
        build/asm/stage2/300.s.o(.bss);
        build/asm/stage2/310.s.o(.bss);
        build/asm/stage2/320.s.o(.bss);
        build/asm/stage2/330.s.o(.bss);
        build/asm/stage2/340.s.o(.bss);
        build/asm/stage2/350.s.o(.bss);
        build/asm/stage2/360.s.o(.bss);
        build/asm/stage2/370.s.o(.bss);
        build/asm/stage2/380.s.o(.bss);
        build/asm/stage2/390.s.o(.bss);
        build/asm/stage2/400.s.o(.bss);
        build/asm/stage2/410.s.o(.bss);
        build/asm/stage2/420.s.o(.bss);
        build/asm/stage2/430.s.o(.bss);
        build/asm/stage2/440.s.o(.bss);
        build/asm/stage2/450.s.o(.bss);
        build/asm/stage2/460.s.o(.bss);
        build/asm/stage2/470.s.o(.bss);
        build/asm/stage2/480.s.o(.bss);
        build/asm/stage2/490.s.o(.bss);
        build/asm/stage2/500.s.o(.bss);
        build/asm/stage2/510.s.o(.bss);
        build/asm/stage2/520.s.o(.bss);
        build/asm/stage2/530.s.o(.bss);
        build/asm/stage2/540.s.o(.bss);
        build/asm/stage2/550.s.o(.bss);
        build/asm/stage2/560.s.o(.bss);
        build/asm/stage2/570.s.o(.bss);
        build/asm/stage2/580.s.o(.bss);
        build/asm/stage2/590.s.o(.bss);
        build/asm/stage2/600.s.o(.bss);
        build/asm/stage2/610.s.o(.bss);
        build/asm/stage2/620.s.o(.bss);
        build/asm/stage2/630.s.o(.bss);
        build/asm/stage2/640.s.o(.bss);
        build/asm/stage2/650.s.o(.bss);
        build/asm/stage2/660.s.o(.bss);
        build/asm/stage2/670.s.o(.bss);
        build/asm/stage2/680.s.o(.bss);
        build/asm/stage2/690.s.o(.bss);
        build/asm/stage2/700.s.o(.bss);
        build/asm/stage2/710.s.o(.bss);
        build/asm/stage2/720.s.o(.bss);
        build/asm/stage2/730.s.o(.bss);
        build/asm/stage2/740.s.o(.bss);
        build/asm/stage2/750.s.o(.bss);
        build/asm/stage2/760.s.o(.bss);
        build/asm/stage2/770.s.o(.bss);
        build/asm/stage2/780.s.o(.bss);
        build/asm/stage2/790.s.o(.bss);
        build/asm/stage2/800.s.o(.bss);
        build/asm/stage2/810.s.o(.bss);
        stage2_BSS_END = .;
    }
    __romPos += SIZEOF(.stage2);
    __romPos = (__romPos + 15) & ~15; /* align 16 */
    stage2_ROM_END = __romPos;
    stage2_VRAM_END = .;

    race_ROM_START = __romPos;
    race_VRAM = ADDR(.race);
    .race 0x800CA7C0 : AT(race_ROM_START) SUBALIGN(16)
    {
        race_RODATA_START = .;
        build/asm/data/race/0x80B80.rodata.s.o(.rodata);
        race_DATA_START = .;
        build/asm/data/race/010.rodata.s.o(.rodata);
        build/asm/data/race/020.rodata.s.o(.rodata);
        build/asm/data/race/025.rodata.s.o(.rodata);
        build/asm/data/race/030.rodata.s.o(.rodata);
        build/asm/data/race/035.rodata.s.o(.rodata);
        build/asm/data/race/040.rodata.s.o(.rodata);
        build/asm/data/race/050.rodata.s.o(.rodata);
        build/asm/data/race/060.rodata.s.o(.rodata);
        build/asm/data/race/070.rodata.s.o(.rodata);
        build/asm/data/race/080.rodata.s.o(.rodata);
        build/asm/data/race/090.rodata.s.o(.rodata);
        build/asm/data/race/100a.rodata.s.o(.rodata);
        build/asm/data/race/100b.rodata.s.o(.rodata);
        build/asm/data/race/110.rodata.s.o(.rodata);
        build/asm/data/race/120.rodata.s.o(.rodata);
        build/asm/data/race/130.rodata.s.o(.rodata);
        build/asm/data/race/140.rodata.s.o(.rodata);
        build/asm/data/race/150.rodata.s.o(.rodata);
        build/asm/data/race/154.rodata.s.o(.rodata);
        build/asm/data/race/157.rodata.s.o(.rodata);
        build/asm/data/race/160.rodata.s.o(.rodata);
        build/asm/data/race/170.rodata.s.o(.rodata);
        build/asm/data/race/180.rodata.s.o(.rodata);
        build/asm/data/race/190.rodata.s.o(.rodata);
        build/asm/data/race/200.rodata.s.o(.rodata);
        build/asm/data/race/210.rodata.s.o(.rodata);
        build/asm/data/race/220.rodata.s.o(.rodata);
        build/asm/data/race/230.rodata.s.o(.rodata);
        build/asm/data/race/240.rodata.s.o(.rodata);
        build/asm/data/race/250.rodata.s.o(.rodata);
        build/asm/data/race/260.rodata.s.o(.rodata);
        build/asm/data/race/265.rodata.s.o(.rodata);
        build/asm/data/race/270.rodata.s.o(.rodata);
        build/asm/data/race/275.rodata.s.o(.rodata);
        build/asm/data/race/280.rodata.s.o(.rodata);
        build/asm/data/race/290.rodata.s.o(.rodata);
        build/asm/data/race/300.rodata.s.o(.rodata);
        build/asm/data/race/310.rodata.s.o(.rodata);
        build/asm/data/race/320.rodata.s.o(.rodata);
        build/asm/data/race/325.rodata.s.o(.rodata);
        build/asm/data/race/330.rodata.s.o(.rodata);
        build/asm/data/race/340.rodata.s.o(.rodata);
        build/asm/data/race/350.rodata.s.o(.rodata);
        build/asm/data/race/360.rodata.s.o(.rodata);
        build/asm/data/race/370.rodata.s.o(.rodata);
        build/asm/data/race/380.rodata.s.o(.rodata);
        build/asm/data/race/390.rodata.s.o(.rodata);
        build/asm/data/race/400.rodata.s.o(.rodata);
        build/asm/data/race/410.rodata.s.o(.rodata);
        build/asm/data/race/420.rodata.s.o(.rodata);
        build/asm/data/race/430.rodata.s.o(.rodata);
        build/asm/data/race/440.rodata.s.o(.rodata);
        build/asm/data/race/450.rodata.s.o(.rodata);
        build/asm/data/race/460.rodata.s.o(.rodata);
        build/asm/data/race/470.rodata.s.o(.rodata);
        build/asm/data/race/480.rodata.s.o(.rodata);
        build/asm/data/race/490.rodata.s.o(.rodata);
        build/asm/data/race/500.rodata.s.o(.rodata);
        build/asm/data/race/510.rodata.s.o(.rodata);
        build/asm/data/race/520.rodata.s.o(.rodata);
        build/asm/data/race/530.rodata.s.o(.rodata);
        build/asm/data/race/540.rodata.s.o(.rodata);
        build/asm/data/race/550.rodata.s.o(.rodata);
        build/asm/data/race/560a.rodata.s.o(.rodata);
        build/asm/data/race/560b.rodata.s.o(.rodata);
        build/asm/data/race/560c.rodata.s.o(.rodata);
        build/asm/data/race/570a.rodata.s.o(.rodata);
        build/asm/data/race/570b.rodata.s.o(.rodata);
        build/asm/data/race/580.rodata.s.o(.rodata);
        build/asm/data/race/590.rodata.s.o(.rodata);
        build/asm/data/race/600.rodata.s.o(.rodata);
        build/asm/data/race/610.rodata.s.o(.rodata);
        build/asm/data/race/620.rodata.s.o(.rodata);
        build/asm/data/race/630.rodata.s.o(.rodata);
        build/asm/data/race/640.rodata.s.o(.rodata);
        build/asm/data/race/650.rodata.s.o(.rodata);
        build/asm/data/race/660a.rodata.s.o(.rodata);
        build/asm/data/race/660b.rodata.s.o(.rodata);
        build/asm/data/race/690.rodata.s.o(.rodata);
        build/asm/data/race/700.rodata.s.o(.rodata);
        build/asm/data/race/720.rodata.s.o(.rodata);
        build/asm/data/race/730.rodata.s.o(.rodata);
        build/asm/data/race/740.rodata.s.o(.rodata);
        build/asm/data/race/750.rodata.s.o(.rodata);
        build/asm/data/race/760.rodata.s.o(.rodata);
        build/asm/data/race/770.rodata.s.o(.rodata);
        build/asm/data/race/780.rodata.s.o(.rodata);
        build/asm/data/race/790.rodata.s.o(.rodata);
        build/asm/data/race/800.rodata.s.o(.rodata);
        build/asm/data/race/810.rodata.s.o(.rodata);
        build/asm/data/race/820.rodata.s.o(.rodata);
        build/asm/data/race/830.rodata.s.o(.rodata);
        build/asm/data/race/835.rodata.s.o(.rodata);
        build/asm/data/race/840.rodata.s.o(.rodata);
        build/asm/data/race/850.rodata.s.o(.rodata);
        build/asm/data/race/860.rodata.s.o(.rodata);
        build/asm/data/race/870.rodata.s.o(.rodata);
        build/asm/data/race/880.rodata.s.o(.rodata);
        build/asm/data/race/890.rodata.s.o(.rodata);
        build/asm/data/race/910.rodata.s.o(.rodata);
        build/asm/data/race/920.rodata.s.o(.rodata);
        build/asm/data/race/930.rodata.s.o(.rodata);
        build/asm/data/race/940.rodata.s.o(.rodata);
        build/asm/data/race/950.rodata.s.o(.rodata);
        build/asm/data/race/960.rodata.s.o(.rodata);
        race_RODATA_END = .;
        race_ctors_640_data__s = .;
        build/asm/data/race/ctors/640.data.s.o(.data);
        race_ctors_660_data__s = .;
        build/asm/data/race/ctors/660.data.s.o(.data);
        race_ctors_710_data__s = .;
        build/asm/data/race/ctors/710.data.s.o(.data);
        race_ctors_880_data__s = .;
        build/asm/data/race/ctors/880.data.s.o(.data);
        race_dtors_660_data__s = .;
        build/asm/data/race/dtors/660.data.s.o(.data);
        race_dtors_710_data__s = .;
        build/asm/data/race/dtors/710.data.s.o(.data);
        race_TEXT_START = .;
        build/asm/race/010.s.o(.text);
        build/asm/race/020.s.o(.text);
        build/asm/race/025.s.o(.text);
        build/asm/race/030.s.o(.text);
        build/asm/race/035.s.o(.text);
        build/asm/race/040.s.o(.text);
        build/asm/race/050.s.o(.text);
        build/asm/race/060.s.o(.text);
        build/asm/race/070.s.o(.text);
        build/asm/race/080.s.o(.text);
        build/asm/race/090.s.o(.text);
        build/asm/race/100.s.o(.text);
        build/asm/race/110.s.o(.text);
        build/asm/race/120.s.o(.text);
        build/asm/race/130.s.o(.text);
        build/asm/race/140.s.o(.text);
        build/asm/race/150.s.o(.text);
        build/asm/race/154.s.o(.text);
        build/asm/race/157.s.o(.text);
        build/asm/race/160.s.o(.text);
        build/asm/race/170.s.o(.text);
        build/asm/race/180.s.o(.text);
        build/asm/race/190.s.o(.text);
        build/asm/race/200.s.o(.text);
        build/asm/race/210.s.o(.text);
        build/asm/race/220.s.o(.text);
        build/asm/race/230.s.o(.text);
        build/asm/race/240.s.o(.text);
        build/asm/race/250.s.o(.text);
        build/asm/race/260.s.o(.text);
        build/asm/race/265.s.o(.text);
        build/asm/race/270.s.o(.text);
        build/asm/race/275.s.o(.text);
        build/asm/race/280.s.o(.text);
        build/asm/race/290.s.o(.text);
        build/asm/race/300.s.o(.text);
        build/asm/race/310.s.o(.text);
        build/asm/race/320.s.o(.text);
        build/asm/race/325.s.o(.text);
        build/asm/race/330.s.o(.text);
        build/asm/race/340.s.o(.text);
        build/asm/race/350.s.o(.text);
        build/asm/race/360.s.o(.text);
        build/asm/race/370.s.o(.text);
        build/asm/race/380.s.o(.text);
        build/asm/race/390.s.o(.text);
        build/asm/race/400.s.o(.text);
        build/asm/race/410.s.o(.text);
        build/asm/race/420.s.o(.text);
        build/asm/race/430.s.o(.text);
        build/asm/race/440.s.o(.text);
        build/asm/race/450.s.o(.text);
        build/asm/race/460.s.o(.text);
        build/asm/race/470.s.o(.text);
        build/asm/race/480.s.o(.text);
        build/asm/race/490.s.o(.text);
        build/asm/race/500.s.o(.text);
        build/asm/race/510.s.o(.text);
        build/asm/race/520.s.o(.text);
        build/asm/race/530.s.o(.text);
        build/asm/race/540.s.o(.text);
        build/asm/race/550.s.o(.text);
        build/asm/race/560a.s.o(.text);
        build/asm/race/560b.s.o(.text);
        build/asm/race/560c.s.o(.text);
        build/asm/race/570.s.o(.text);
        build/asm/race/580.s.o(.text);
        build/asm/race/590.s.o(.text);
        build/asm/race/600.s.o(.text);
        build/asm/race/610.s.o(.text);
        build/asm/race/620.s.o(.text);
        build/asm/race/630.s.o(.text);
        build/asm/race/640.s.o(.text);
        build/asm/race/650.s.o(.text);
        build/asm/race/660.s.o(.text);
        build/asm/race/670.s.o(.text);
        build/asm/race/680.s.o(.text);
        build/asm/race/690.s.o(.text);
        build/asm/race/700.s.o(.text);
        build/asm/race/710.s.o(.text);
        build/asm/race/720.s.o(.text);
        build/asm/race/730.s.o(.text);
        build/asm/race/740.s.o(.text);
        build/asm/race/750.s.o(.text);
        build/asm/race/760.s.o(.text);
        build/asm/race/770.s.o(.text);
        build/asm/race/780.s.o(.text);
        build/asm/race/790.s.o(.text);
        build/asm/race/800.s.o(.text);
        build/asm/race/810.s.o(.text);
        build/asm/race/820.s.o(.text);
        build/asm/race/830.s.o(.text);
        build/asm/race/835.s.o(.text);
        build/asm/race/840.s.o(.text);
        build/asm/race/850.s.o(.text);
        build/asm/race/860.s.o(.text);
        build/asm/race/870.s.o(.text);
        build/asm/race/880.s.o(.text);
        build/asm/race/890.s.o(.text);
        build/asm/race/900.s.o(.text);
        build/asm/race/910.s.o(.text);
        build/asm/race/920.s.o(.text);
        build/asm/race/930.s.o(.text);
        build/asm/race/940.s.o(.text);
        build/asm/race/950.s.o(.text);
        build/asm/race/960.s.o(.text);
        race_TEXT_END = .;
        race_030_data__s = .;
        build/asm/data/race/030.data.s.o(.data);
        race_035_data__s = .;
        build/asm/data/race/035.data.s.o(.data);
        race_100_data__s = .;
        build/asm/data/race/100.data.s.o(.data);
        race_170_data__s = .;
        build/asm/data/race/170.data.s.o(.data);
        race_180_data__s = .;
        build/asm/data/race/180.data.s.o(.data);
        race_210_data__s = .;
        build/asm/data/race/210.data.s.o(.data);
        race_0xE8490_data__s = .;
        build/asm/data/race/0xE8490.data.s.o(.data);
        race_220_data__s = .;
        build/asm/data/race/220.data.s.o(.data);
        race_230_data__s = .;
        build/asm/data/race/230.data.s.o(.data);
        race_260_data__s = .;
        build/asm/data/race/260.data.s.o(.data);
        race_280_data__s = .;
        build/asm/data/race/280.data.s.o(.data);
        race_360_data__s = .;
        build/asm/data/race/360.data.s.o(.data);
        race_370_data__s = .;
        build/asm/data/race/370.data.s.o(.data);
        race_400_data__s = .;
        build/asm/data/race/400.data.s.o(.data);
        race_440_data__s = .;
        build/asm/data/race/440.data.s.o(.data);
        race_470_data__s = .;
        build/asm/data/race/470.data.s.o(.data);
        race_510_data__s = .;
        build/asm/data/race/510.data.s.o(.data);
        race_530_data__s = .;
        build/asm/data/race/530.data.s.o(.data);
        race_560a_data__s = .;
        build/asm/data/race/560a.data.s.o(.data);
        race_560c_data__s = .;
        build/asm/data/race/560c.data.s.o(.data);
        race_600_data__s = .;
        build/asm/data/race/600.data.s.o(.data);
        race_640_data__s = .;
        build/asm/data/race/640.data.s.o(.data);
        race_730_data__s = .;
        build/asm/data/race/730.data.s.o(.data);
        race_770_data__s = .;
        build/asm/data/race/770.data.s.o(.data);
        race_810_data__s = .;
        build/asm/data/race/810.data.s.o(.data);
        race_820_data__s = .;
        build/asm/data/race/820.data.s.o(.data);
        race_850_data__s = .;
        build/asm/data/race/850.data.s.o(.data);
        race_880_data__s = .;
        build/asm/data/race/880.data.s.o(.data);
        race_910_data__s = .;
        build/asm/data/race/910.data.s.o(.data);
        race_950_data__s = .;
        build/asm/data/race/950.data.s.o(.data);
        race_DATA_END = .;
    }
    race_bss_VRAM = ADDR(.race_bss);
    .race_bss (NOLOAD) : SUBALIGN(16)
    {
        race_BSS_START = .;
        build/asm/race/010.s.o(.bss);
        build/asm/race/020.s.o(.bss);
        build/asm/race/025.s.o(.bss);
        build/asm/race/030.s.o(.bss);
        build/asm/race/035.s.o(.bss);
        build/asm/race/040.s.o(.bss);
        build/asm/race/050.s.o(.bss);
        build/asm/race/060.s.o(.bss);
        build/asm/race/070.s.o(.bss);
        build/asm/race/080.s.o(.bss);
        build/asm/race/090.s.o(.bss);
        build/asm/race/100.s.o(.bss);
        build/asm/race/110.s.o(.bss);
        build/asm/race/120.s.o(.bss);
        build/asm/race/130.s.o(.bss);
        build/asm/race/140.s.o(.bss);
        build/asm/race/150.s.o(.bss);
        build/asm/race/154.s.o(.bss);
        build/asm/race/157.s.o(.bss);
        build/asm/race/160.s.o(.bss);
        build/asm/race/170.s.o(.bss);
        build/asm/race/180.s.o(.bss);
        build/asm/race/190.s.o(.bss);
        build/asm/race/200.s.o(.bss);
        build/asm/race/210.s.o(.bss);
        build/asm/race/220.s.o(.bss);
        build/asm/race/230.s.o(.bss);
        build/asm/race/240.s.o(.bss);
        build/asm/race/250.s.o(.bss);
        build/asm/race/260.s.o(.bss);
        build/asm/race/265.s.o(.bss);
        build/asm/race/270.s.o(.bss);
        build/asm/race/275.s.o(.bss);
        build/asm/race/280.s.o(.bss);
        build/asm/race/290.s.o(.bss);
        build/asm/race/300.s.o(.bss);
        build/asm/race/310.s.o(.bss);
        build/asm/race/320.s.o(.bss);
        build/asm/race/325.s.o(.bss);
        build/asm/race/330.s.o(.bss);
        build/asm/race/340.s.o(.bss);
        build/asm/race/350.s.o(.bss);
        build/asm/race/360.s.o(.bss);
        build/asm/race/370.s.o(.bss);
        build/asm/race/380.s.o(.bss);
        build/asm/race/390.s.o(.bss);
        build/asm/race/400.s.o(.bss);
        build/asm/race/410.s.o(.bss);
        build/asm/race/420.s.o(.bss);
        build/asm/race/430.s.o(.bss);
        build/asm/race/440.s.o(.bss);
        build/asm/race/450.s.o(.bss);
        build/asm/race/460.s.o(.bss);
        build/asm/race/470.s.o(.bss);
        build/asm/race/480.s.o(.bss);
        build/asm/race/490.s.o(.bss);
        build/asm/race/500.s.o(.bss);
        build/asm/race/510.s.o(.bss);
        build/asm/race/520.s.o(.bss);
        build/asm/race/530.s.o(.bss);
        build/asm/race/540.s.o(.bss);
        build/asm/race/550.s.o(.bss);
        build/asm/race/560a.s.o(.bss);
        build/asm/race/560b.s.o(.bss);
        build/asm/race/560c.s.o(.bss);
        build/asm/race/570.s.o(.bss);
        build/asm/race/580.s.o(.bss);
        build/asm/race/590.s.o(.bss);
        build/asm/race/600.s.o(.bss);
        build/asm/race/610.s.o(.bss);
        build/asm/race/620.s.o(.bss);
        build/asm/race/630.s.o(.bss);
        build/asm/race/640.s.o(.bss);
        build/asm/race/650.s.o(.bss);
        build/asm/race/660.s.o(.bss);
        build/asm/race/670.s.o(.bss);
        build/asm/race/680.s.o(.bss);
        build/asm/race/690.s.o(.bss);
        build/asm/race/700.s.o(.bss);
        build/asm/race/710.s.o(.bss);
        build/asm/race/720.s.o(.bss);
        build/asm/race/730.s.o(.bss);
        build/asm/race/740.s.o(.bss);
        build/asm/race/750.s.o(.bss);
        build/asm/race/760.s.o(.bss);
        build/asm/race/770.s.o(.bss);
        build/asm/race/780.s.o(.bss);
        build/asm/race/790.s.o(.bss);
        build/asm/race/800.s.o(.bss);
        build/asm/race/810.s.o(.bss);
        build/asm/race/820.s.o(.bss);
        build/asm/race/830.s.o(.bss);
        build/asm/race/835.s.o(.bss);
        build/asm/race/840.s.o(.bss);
        build/asm/race/850.s.o(.bss);
        build/asm/race/860.s.o(.bss);
        build/asm/race/870.s.o(.bss);
        build/asm/race/880.s.o(.bss);
        build/asm/race/890.s.o(.bss);
        build/asm/race/900.s.o(.bss);
        build/asm/race/910.s.o(.bss);
        build/asm/race/920.s.o(.bss);
        build/asm/race/930.s.o(.bss);
        build/asm/race/940.s.o(.bss);
        build/asm/race/950.s.o(.bss);
        build/asm/race/960.s.o(.bss);
        race_BSS_END = .;
    }
    __romPos += SIZEOF(.race);
    __romPos = (__romPos + 15) & ~15; /* align 16 */
    race_ROM_END = __romPos;
    race_VRAM_END = .;

    menu_ROM_START = __romPos;
    menu_VRAM = ADDR(.menu);
    .menu 0x800CA7C0 : AT(menu_ROM_START) SUBALIGN(16)
    {
        menu_RODATA_START = .;
        build/asm/data/menu/0.rdata.s.o(.rdata);
        menu_DATA_START = .;
        build/asm/data/menu/010.rdata.s.o(.rdata);
        build/asm/data/menu/020.rdata.s.o(.rdata);
        build/asm/data/menu/020-030.rdata.s.o(.rdata);
        build/asm/data/menu/050.rdata.s.o(.rdata);
        build/asm/data/menu/050-060.rdata.s.o(.rdata);
        build/asm/data/menu/080-150.rdata.s.o(.rdata);
        build/asm/data/menu/160-180.rdata.s.o(.rdata);
        build/asm/data/menu/180b.rdata.s.o(.rdata);
        build/asm/data/menu/180c.rdata.s.o(.rdata);
        build/asm/data/menu/190-210.rdata.s.o(.rdata);
        build/asm/data/menu/220.rdata.s.o(.rdata);
        build/asm/data/menu/230.rdata.s.o(.rdata);
        build/asm/data/menu/240a.rdata.s.o(.rdata);
        build/asm/data/menu/240b.rdata.s.o(.rdata);
        build/asm/data/menu/260.rdata.s.o(.rdata);
        build/asm/data/menu/270-290.rdata.s.o(.rdata);
        build/asm/data/menu/300.rdata.s.o(.rdata);
        build/asm/data/menu/320-330a.rdata.s.o(.rdata);
        build/asm/data/menu/330b.rdata.s.o(.rdata);
        build/asm/data/menu/330c-370.rdata.s.o(.rdata);
        build/asm/data/menu/380-390.rdata.s.o(.rdata);
        build/asm/data/menu/400.rdata.s.o(.rdata);
        build/asm/data/menu/410.rdata.s.o(.rdata);
        build/asm/data/menu/420-430.rdata.s.o(.rdata);
        build/asm/data/menu/440.rdata.s.o(.rdata);
        build/asm/data/menu/450.rdata.s.o(.rdata);
        build/asm/data/menu/450-460.rdata.s.o(.rdata);
        build/asm/data/menu/470.rdata.s.o(.rdata);
        build/asm/data/menu/480.rdata.s.o(.rdata);
        build/asm/data/menu/490a.rdata.s.o(.rdata);
        build/asm/data/menu/490b.rdata.s.o(.rdata);
        build/asm/data/menu/490c.rdata.s.o(.rdata);
        build/asm/data/menu/490d.rdata.s.o(.rdata);
        build/asm/data/menu/500-520.rdata.s.o(.rdata);
        build/asm/data/menu/530.rdata.s.o(.rdata);
        build/asm/data/menu/540.rdata.s.o(.rdata);
        build/asm/data/menu/560.rdata.s.o(.rdata);
        build/asm/data/menu/570.rdata.s.o(.rdata);
        build/asm/data/menu/580-590a.rdata.s.o(.rdata);
        build/asm/data/menu/590b.rdata.s.o(.rdata);
        build/asm/data/menu/600-610.rdata.s.o(.rdata);
        build/asm/data/menu/620.rdata.s.o(.rdata);
        build/asm/data/menu/630a.rdata.s.o(.rdata);
        build/asm/data/menu/630b-670.rdata.s.o(.rdata);
        build/asm/data/menu/680.rdata.s.o(.rdata);
        build/asm/data/menu/690.rdata.s.o(.rdata);
        build/asm/data/menu/700-710.rdata.s.o(.rdata);
        build/asm/data/menu/720-730.rdata.s.o(.rdata);
        build/asm/data/menu/740.rdata.s.o(.rdata);
        build/asm/data/menu/760.rdata.s.o(.rdata);
        build/asm/data/menu/770.rdata.s.o(.rdata);
        build/asm/data/menu/780.rdata.s.o(.rdata);
        build/asm/data/menu/790-810.rdata.s.o(.rdata);
        build/asm/data/menu/820.rdata.s.o(.rdata);
        build/asm/data/menu/830-840.rdata.s.o(.rdata);
        build/asm/data/menu/840b.rdata.s.o(.rdata);
        build/asm/data/menu/850-860.rdata.s.o(.rdata);
        build/asm/data/menu/870.rdata.s.o(.rdata);
        build/asm/data/menu/880.rdata.s.o(.rdata);
        build/asm/data/menu/890a.rdata.s.o(.rdata);
        build/asm/data/menu/890b.rdata.s.o(.rdata);
        build/asm/data/menu/900.rdata.s.o(.rdata);
        build/asm/data/menu/910a.rdata.s.o(.rdata);
        build/asm/data/menu/910b.rdata.s.o(.rdata);
        build/asm/data/menu/920-940.rdata.s.o(.rdata);
        build/asm/data/menu/950.rdata.s.o(.rdata);
        build/asm/data/menu/960a.rdata.s.o(.rdata);
        build/asm/data/menu/960b.rdata.s.o(.rdata);
        build/asm/data/menu/970-980.rdata.s.o(.rdata);
        build/asm/data/menu/980.rdata.s.o(.rdata);
        menu_TEXT_START = .;
        build/asm/menu/010.s.o(.text);
        build/asm/menu/020.s.o(.text);
        build/asm/menu/030.s.o(.text);
        build/asm/menu/040.s.o(.text);
        build/asm/menu/050.s.o(.text);
        build/asm/menu/060.s.o(.text);
        build/asm/menu/070.s.o(.text);
        build/asm/menu/080.s.o(.text);
        build/asm/menu/090.s.o(.text);
        build/asm/menu/100.s.o(.text);
        build/asm/menu/110.s.o(.text);
        build/asm/menu/120.s.o(.text);
        build/asm/menu/130.s.o(.text);
        build/asm/menu/140.s.o(.text);
        build/asm/menu/150.s.o(.text);
        build/asm/menu/160.s.o(.text);
        build/asm/menu/170.s.o(.text);
        build/asm/menu/180.s.o(.text);
        build/asm/menu/190.s.o(.text);
        build/asm/menu/200.s.o(.text);
        build/asm/menu/210.s.o(.text);
        build/asm/menu/220.s.o(.text);
        build/asm/menu/230.s.o(.text);
        build/asm/menu/240.s.o(.text);
        build/asm/menu/250.s.o(.text);
        build/asm/menu/260.s.o(.text);
        build/asm/menu/270.s.o(.text);
        build/asm/menu/280.s.o(.text);
        build/asm/menu/290.s.o(.text);
        build/asm/menu/300.s.o(.text);
        build/asm/menu/310.s.o(.text);
        build/asm/menu/320.s.o(.text);
        build/asm/menu/330.s.o(.text);
        build/asm/menu/340.s.o(.text);
        build/asm/menu/350.s.o(.text);
        build/asm/menu/360.s.o(.text);
        build/asm/menu/370.s.o(.text);
        build/asm/menu/380.s.o(.text);
        build/asm/menu/390.s.o(.text);
        build/asm/menu/400.s.o(.text);
        build/asm/menu/410.s.o(.text);
        build/asm/menu/420.s.o(.text);
        build/asm/menu/430.s.o(.text);
        build/asm/menu/440.s.o(.text);
        build/asm/menu/450.s.o(.text);
        build/asm/menu/460.s.o(.text);
        build/asm/menu/470.s.o(.text);
        build/asm/menu/480.s.o(.text);
        build/asm/menu/490.s.o(.text);
        build/asm/menu/500.s.o(.text);
        build/asm/menu/510.s.o(.text);
        build/asm/menu/520.s.o(.text);
        build/asm/menu/530.s.o(.text);
        build/asm/menu/540.s.o(.text);
        build/asm/menu/550.s.o(.text);
        build/asm/menu/560.s.o(.text);
        build/asm/menu/570.s.o(.text);
        build/asm/menu/580.s.o(.text);
        build/asm/menu/590.s.o(.text);
        build/asm/menu/600.s.o(.text);
        build/asm/menu/610.s.o(.text);
        build/asm/menu/620.s.o(.text);
        build/asm/menu/630.s.o(.text);
        build/asm/menu/640.s.o(.text);
        build/asm/menu/650.s.o(.text);
        build/asm/menu/660.s.o(.text);
        build/asm/menu/670.s.o(.text);
        build/asm/menu/680.s.o(.text);
        build/asm/menu/690.s.o(.text);
        build/asm/menu/700.s.o(.text);
        build/asm/menu/710.s.o(.text);
        build/asm/menu/720.s.o(.text);
        build/asm/menu/730.s.o(.text);
        build/asm/menu/740.s.o(.text);
        build/asm/menu/750.s.o(.text);
        build/asm/menu/760.s.o(.text);
        build/asm/menu/770.s.o(.text);
        build/asm/menu/780.s.o(.text);
        build/asm/menu/790.s.o(.text);
        build/asm/menu/800.s.o(.text);
        build/asm/menu/810.s.o(.text);
        build/asm/menu/820.s.o(.text);
        build/asm/menu/830.s.o(.text);
        build/asm/menu/840.s.o(.text);
        build/asm/menu/850.s.o(.text);
        build/asm/menu/860.s.o(.text);
        build/asm/menu/870.s.o(.text);
        build/asm/menu/880.s.o(.text);
        build/asm/menu/890.s.o(.text);
        build/asm/menu/900.s.o(.text);
        build/asm/menu/910.s.o(.text);
        build/asm/menu/920.s.o(.text);
        build/asm/menu/930.s.o(.text);
        build/asm/menu/940.s.o(.text);
        build/asm/menu/950.s.o(.text);
        build/asm/menu/960.s.o(.text);
        build/asm/menu/970.s.o(.text);
        build/asm/menu/980.s.o(.text);
        menu_TEXT_END = .;
        menu_144A40_data__s = .;
        build/asm/data/menu/144A40.data.s.o(.data);
        menu_144A50_data__s = .;
        build/asm/data/menu/144A50.data.s.o(.data);
        menu_020_data__s = .;
        build/asm/data/menu/020.data.s.o(.data);
        menu_144A70_data__s = .;
        build/asm/data/menu/144A70.data.s.o(.data);
        menu_050a_data__s = .;
        build/asm/data/menu/050a.data.s.o(.data);
        menu_050b_data__s = .;
        build/asm/data/menu/050b.data.s.o(.data);
        menu_070_data__s = .;
        build/asm/data/menu/070.data.s.o(.data);
        menu_080_data__s = .;
        build/asm/data/menu/080.data.s.o(.data);
        menu_090_data__s = .;
        build/asm/data/menu/090.data.s.o(.data);
        menu_100_data__s = .;
        build/asm/data/menu/100.data.s.o(.data);
        menu_144AF0_data__s = .;
        build/asm/data/menu/144AF0.data.s.o(.data);
        menu_144B00_data__s = .;
        build/asm/data/menu/144B00.data.s.o(.data);
        menu_180_data__s = .;
        build/asm/data/menu/180.data.s.o(.data);
        menu_190_data__s = .;
        build/asm/data/menu/190.data.s.o(.data);
        menu_210_data__s = .;
        build/asm/data/menu/210.data.s.o(.data);
        menu_220_data__s = .;
        build/asm/data/menu/220.data.s.o(.data);
        menu_230_data__s = .;
        build/asm/data/menu/230.data.s.o(.data);
        menu_240_data__s = .;
        build/asm/data/menu/240.data.s.o(.data);
        menu_250_data__s = .;
        build/asm/data/menu/250.data.s.o(.data);
        menu_270_data__s = .;
        build/asm/data/menu/270.data.s.o(.data);
        menu_144CD0_data__s = .;
        build/asm/data/menu/144CD0.data.s.o(.data);
        menu_300_data__s = .;
        build/asm/data/menu/300.data.s.o(.data);
        menu_320_data__s = .;
        build/asm/data/menu/320.data.s.o(.data);
        menu_330a_data__s = .;
        build/asm/data/menu/330a.data.s.o(.data);
        menu_330b_data__s = .;
        build/asm/data/menu/330b.data.s.o(.data);
        menu_360_data__s = .;
        build/asm/data/menu/360.data.s.o(.data);
        menu_370_data__s = .;
        build/asm/data/menu/370.data.s.o(.data);
        menu_144D80_data__s = .;
        build/asm/data/menu/144D80.data.s.o(.data);
        menu_144D90_data__s = .;
        build/asm/data/menu/144D90.data.s.o(.data);
        menu_144FA0_data__s = .;
        build/asm/data/menu/144FA0.data.s.o(.data);
        menu_144FB0_data__s = .;
        build/asm/data/menu/144FB0.data.s.o(.data);
        menu_144FC0_data__s = .;
        build/asm/data/menu/144FC0.data.s.o(.data);
        menu_144FD0_data__s = .;
        build/asm/data/menu/144FD0.data.s.o(.data);
        menu_440_data__s = .;
        build/asm/data/menu/440.data.s.o(.data);
        menu_450a_data__s = .;
        build/asm/data/menu/450a.data.s.o(.data);
        menu_450b_data__s = .;
        build/asm/data/menu/450b.data.s.o(.data);
        menu_460_data__s = .;
        build/asm/data/menu/460.data.s.o(.data);
        menu_145080_data__s = .;
        build/asm/data/menu/145080.data.s.o(.data);
        menu_145090_data__s = .;
        build/asm/data/menu/145090.data.s.o(.data);
        menu_1450A0_data__s = .;
        build/asm/data/menu/1450A0.data.s.o(.data);
        menu_1450B0_data__s = .;
        build/asm/data/menu/1450B0.data.s.o(.data);
        menu_510_data__s = .;
        build/asm/data/menu/510.data.s.o(.data);
        menu_1450E0_data__s = .;
        build/asm/data/menu/1450E0.data.s.o(.data);
        menu_1450F0_data__s = .;
        build/asm/data/menu/1450F0.data.s.o(.data);
        menu_145100_data__s = .;
        build/asm/data/menu/145100.data.s.o(.data);
        menu_145110_data__s = .;
        build/asm/data/menu/145110.data.s.o(.data);
        menu_145120_data__s = .;
        build/asm/data/menu/145120.data.s.o(.data);
        menu_145130_data__s = .;
        build/asm/data/menu/145130.data.s.o(.data);
        menu_145140_data__s = .;
        build/asm/data/menu/145140.data.s.o(.data);
        menu_145150_data__s = .;
        build/asm/data/menu/145150.data.s.o(.data);
        menu_590_data__s = .;
        build/asm/data/menu/590.data.s.o(.data);
        menu_145190_data__s = .;
        build/asm/data/menu/145190.data.s.o(.data);
        menu_1451A0_data__s = .;
        build/asm/data/menu/1451A0.data.s.o(.data);
        menu_1451B0_data__s = .;
        build/asm/data/menu/1451B0.data.s.o(.data);
        menu_1451C0_data__s = .;
        build/asm/data/menu/1451C0.data.s.o(.data);
        menu_630_data__s = .;
        build/asm/data/menu/630.data.s.o(.data);
        menu_145210_data__s = .;
        build/asm/data/menu/145210.data.s.o(.data);
        menu_145220_data__s = .;
        build/asm/data/menu/145220.data.s.o(.data);
        menu_145230_data__s = .;
        build/asm/data/menu/145230.data.s.o(.data);
        menu_780_data__s = .;
        build/asm/data/menu/780.data.s.o(.data);
        menu_790_data__s = .;
        build/asm/data/menu/790.data.s.o(.data);
        menu_145260_data__s = .;
        build/asm/data/menu/145260.data.s.o(.data);
        menu_145270_data__s = .;
        build/asm/data/menu/145270.data.s.o(.data);
        menu_DATA_END = .;
        build/asm/menu/010.s.o(.rodata);
        build/asm/menu/020.s.o(.rodata);
        build/asm/menu/030.s.o(.rodata);
        build/asm/menu/040.s.o(.rodata);
        build/asm/menu/050.s.o(.rodata);
        build/asm/menu/060.s.o(.rodata);
        build/asm/menu/070.s.o(.rodata);
        build/asm/menu/080.s.o(.rodata);
        build/asm/menu/090.s.o(.rodata);
        build/asm/menu/100.s.o(.rodata);
        build/asm/menu/110.s.o(.rodata);
        build/asm/menu/120.s.o(.rodata);
        build/asm/menu/130.s.o(.rodata);
        build/asm/menu/140.s.o(.rodata);
        build/asm/menu/150.s.o(.rodata);
        build/asm/menu/160.s.o(.rodata);
        build/asm/menu/170.s.o(.rodata);
        build/asm/menu/180.s.o(.rodata);
        build/asm/menu/190.s.o(.rodata);
        build/asm/menu/200.s.o(.rodata);
        build/asm/menu/210.s.o(.rodata);
        build/asm/menu/220.s.o(.rodata);
        build/asm/menu/230.s.o(.rodata);
        build/asm/menu/240.s.o(.rodata);
        build/asm/menu/250.s.o(.rodata);
        build/asm/menu/260.s.o(.rodata);
        build/asm/menu/270.s.o(.rodata);
        build/asm/menu/280.s.o(.rodata);
        build/asm/menu/290.s.o(.rodata);
        build/asm/menu/300.s.o(.rodata);
        build/asm/menu/310.s.o(.rodata);
        build/asm/menu/320.s.o(.rodata);
        build/asm/menu/330.s.o(.rodata);
        build/asm/menu/340.s.o(.rodata);
        build/asm/menu/350.s.o(.rodata);
        build/asm/menu/360.s.o(.rodata);
        build/asm/menu/370.s.o(.rodata);
        build/asm/menu/380.s.o(.rodata);
        build/asm/menu/390.s.o(.rodata);
        build/asm/menu/400.s.o(.rodata);
        build/asm/menu/410.s.o(.rodata);
        build/asm/menu/420.s.o(.rodata);
        build/asm/menu/430.s.o(.rodata);
        build/asm/menu/440.s.o(.rodata);
        build/asm/menu/450.s.o(.rodata);
        build/asm/menu/460.s.o(.rodata);
        build/asm/menu/470.s.o(.rodata);
        build/asm/menu/480.s.o(.rodata);
        build/asm/menu/490.s.o(.rodata);
        build/asm/menu/500.s.o(.rodata);
        build/asm/menu/510.s.o(.rodata);
        build/asm/menu/520.s.o(.rodata);
        build/asm/menu/530.s.o(.rodata);
        build/asm/menu/540.s.o(.rodata);
        build/asm/menu/550.s.o(.rodata);
        build/asm/menu/560.s.o(.rodata);
        build/asm/menu/570.s.o(.rodata);
        build/asm/menu/580.s.o(.rodata);
        build/asm/menu/590.s.o(.rodata);
        build/asm/menu/600.s.o(.rodata);
        build/asm/menu/610.s.o(.rodata);
        build/asm/menu/620.s.o(.rodata);
        build/asm/menu/630.s.o(.rodata);
        build/asm/menu/640.s.o(.rodata);
        build/asm/menu/650.s.o(.rodata);
        build/asm/menu/660.s.o(.rodata);
        build/asm/menu/670.s.o(.rodata);
        build/asm/menu/680.s.o(.rodata);
        build/asm/menu/690.s.o(.rodata);
        build/asm/menu/700.s.o(.rodata);
        build/asm/menu/710.s.o(.rodata);
        build/asm/menu/720.s.o(.rodata);
        build/asm/menu/730.s.o(.rodata);
        build/asm/menu/740.s.o(.rodata);
        build/asm/menu/750.s.o(.rodata);
        build/asm/menu/760.s.o(.rodata);
        build/asm/menu/770.s.o(.rodata);
        build/asm/menu/780.s.o(.rodata);
        build/asm/menu/790.s.o(.rodata);
        build/asm/menu/800.s.o(.rodata);
        build/asm/menu/810.s.o(.rodata);
        build/asm/menu/820.s.o(.rodata);
        build/asm/menu/830.s.o(.rodata);
        build/asm/menu/840.s.o(.rodata);
        build/asm/menu/850.s.o(.rodata);
        build/asm/menu/860.s.o(.rodata);
        build/asm/menu/870.s.o(.rodata);
        build/asm/menu/880.s.o(.rodata);
        build/asm/menu/890.s.o(.rodata);
        build/asm/menu/900.s.o(.rodata);
        build/asm/menu/910.s.o(.rodata);
        build/asm/menu/920.s.o(.rodata);
        build/asm/menu/930.s.o(.rodata);
        build/asm/menu/940.s.o(.rodata);
        build/asm/menu/950.s.o(.rodata);
        build/asm/menu/960.s.o(.rodata);
        build/asm/menu/970.s.o(.rodata);
        build/asm/menu/980.s.o(.rodata);
        menu_RODATA_END = .;
    }
    menu_bss_VRAM = ADDR(.menu_bss);
    .menu_bss (NOLOAD) : SUBALIGN(16)
    {
        menu_BSS_START = .;
        build/asm/menu/010.s.o(.bss);
        build/asm/menu/020.s.o(.bss);
        build/asm/menu/030.s.o(.bss);
        build/asm/menu/040.s.o(.bss);
        build/asm/menu/050.s.o(.bss);
        build/asm/menu/060.s.o(.bss);
        build/asm/menu/070.s.o(.bss);
        build/asm/menu/080.s.o(.bss);
        build/asm/menu/090.s.o(.bss);
        build/asm/menu/100.s.o(.bss);
        build/asm/menu/110.s.o(.bss);
        build/asm/menu/120.s.o(.bss);
        build/asm/menu/130.s.o(.bss);
        build/asm/menu/140.s.o(.bss);
        build/asm/menu/150.s.o(.bss);
        build/asm/menu/160.s.o(.bss);
        build/asm/menu/170.s.o(.bss);
        build/asm/menu/180.s.o(.bss);
        build/asm/menu/190.s.o(.bss);
        build/asm/menu/200.s.o(.bss);
        build/asm/menu/210.s.o(.bss);
        build/asm/menu/220.s.o(.bss);
        build/asm/menu/230.s.o(.bss);
        build/asm/menu/240.s.o(.bss);
        build/asm/menu/250.s.o(.bss);
        build/asm/menu/260.s.o(.bss);
        build/asm/menu/270.s.o(.bss);
        build/asm/menu/280.s.o(.bss);
        build/asm/menu/290.s.o(.bss);
        build/asm/menu/300.s.o(.bss);
        build/asm/menu/310.s.o(.bss);
        build/asm/menu/320.s.o(.bss);
        build/asm/menu/330.s.o(.bss);
        build/asm/menu/340.s.o(.bss);
        build/asm/menu/350.s.o(.bss);
        build/asm/menu/360.s.o(.bss);
        build/asm/menu/370.s.o(.bss);
        build/asm/menu/380.s.o(.bss);
        build/asm/menu/390.s.o(.bss);
        build/asm/menu/400.s.o(.bss);
        build/asm/menu/410.s.o(.bss);
        build/asm/menu/420.s.o(.bss);
        build/asm/menu/430.s.o(.bss);
        build/asm/menu/440.s.o(.bss);
        build/asm/menu/450.s.o(.bss);
        build/asm/menu/460.s.o(.bss);
        build/asm/menu/470.s.o(.bss);
        build/asm/menu/480.s.o(.bss);
        build/asm/menu/490.s.o(.bss);
        build/asm/menu/500.s.o(.bss);
        build/asm/menu/510.s.o(.bss);
        build/asm/menu/520.s.o(.bss);
        build/asm/menu/530.s.o(.bss);
        build/asm/menu/540.s.o(.bss);
        build/asm/menu/550.s.o(.bss);
        build/asm/menu/560.s.o(.bss);
        build/asm/menu/570.s.o(.bss);
        build/asm/menu/580.s.o(.bss);
        build/asm/menu/590.s.o(.bss);
        build/asm/menu/600.s.o(.bss);
        build/asm/menu/610.s.o(.bss);
        build/asm/menu/620.s.o(.bss);
        build/asm/menu/630.s.o(.bss);
        build/asm/menu/640.s.o(.bss);
        build/asm/menu/650.s.o(.bss);
        build/asm/menu/660.s.o(.bss);
        build/asm/menu/670.s.o(.bss);
        build/asm/menu/680.s.o(.bss);
        build/asm/menu/690.s.o(.bss);
        build/asm/menu/700.s.o(.bss);
        build/asm/menu/710.s.o(.bss);
        build/asm/menu/720.s.o(.bss);
        build/asm/menu/730.s.o(.bss);
        build/asm/menu/740.s.o(.bss);
        build/asm/menu/750.s.o(.bss);
        build/asm/menu/760.s.o(.bss);
        build/asm/menu/770.s.o(.bss);
        build/asm/menu/780.s.o(.bss);
        build/asm/menu/790.s.o(.bss);
        build/asm/menu/800.s.o(.bss);
        build/asm/menu/810.s.o(.bss);
        build/asm/menu/820.s.o(.bss);
        build/asm/menu/830.s.o(.bss);
        build/asm/menu/840.s.o(.bss);
        build/asm/menu/850.s.o(.bss);
        build/asm/menu/860.s.o(.bss);
        build/asm/menu/870.s.o(.bss);
        build/asm/menu/880.s.o(.bss);
        build/asm/menu/890.s.o(.bss);
        build/asm/menu/900.s.o(.bss);
        build/asm/menu/910.s.o(.bss);
        build/asm/menu/920.s.o(.bss);
        build/asm/menu/930.s.o(.bss);
        build/asm/menu/940.s.o(.bss);
        build/asm/menu/950.s.o(.bss);
        build/asm/menu/960.s.o(.bss);
        build/asm/menu/970.s.o(.bss);
        build/asm/menu/980.s.o(.bss);
        menu_BSS_END = .;
    }
    __romPos += SIZEOF(.menu);
    __romPos = (__romPos + 15) & ~15; /* align 16 */
    menu_ROM_END = __romPos;
    menu_VRAM_END = .;

    ljam_ROM_START = __romPos;
    ljam_VRAM = ADDR(.ljam);
    .ljam : AT(ljam_ROM_START) SUBALIGN(16)
    {
        ljam_DATA_START = .;
        ljam_bin = .;
        build/assets/ljam.bin.o(.data);
        ljam_DATA_END = .;
    }
    __romPos += SIZEOF(.ljam);
    ljam_ROM_END = __romPos;
    ljam_VRAM_END = .;

    /DISCARD/ :
    {
        *(*);
    }
}
